# STM32MP25_CM33 register map
File version: 1.3
CPU: CM33 r0p1, little endian, MPU, FPU, vendor SysTick, 8 interrupt priority bits
Registers are 32-bit, read-write, reset 0x0 unless marked. A register's access mark holds for its fields unless they carry their own. Offsets are from the block's base; [hi:lo] are bit positions; {n}, {i} and the like mark numbered series; 'fields as' and 'values as' point back to an identical list.

## RIFSC — RIFSC register block
Base 0x42080000
Same registers: RIFSC_S 0x52080000
0x00 RIFSC_RISC_CR — RIFSC RISC slave configuration register x
  [0] GLOCK — Global lock This bit locks the configuration of RIFSC RISC registers until next reset. This bit is cleared by default and, once set, it cannot be reset until global RIFSC reset.
    0=RIFSC RISC registers are writable; 1=All writes to RIFSC RISC registers are ignored, except RIFSC_RISC_PERy_SEMCR
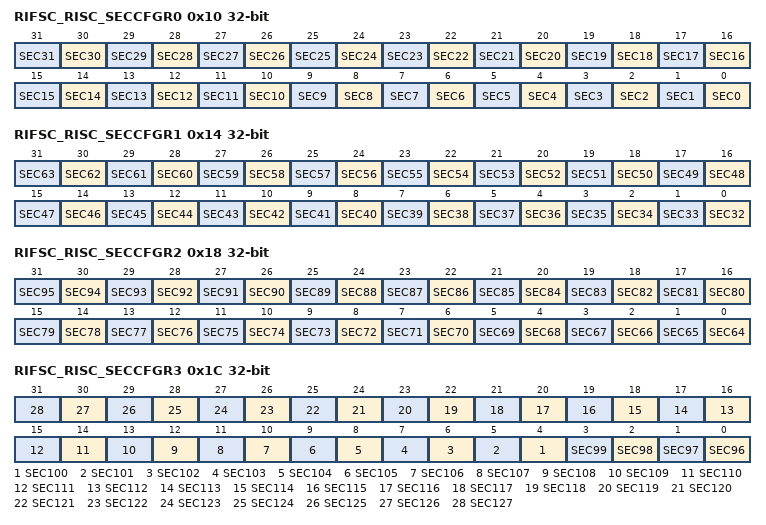
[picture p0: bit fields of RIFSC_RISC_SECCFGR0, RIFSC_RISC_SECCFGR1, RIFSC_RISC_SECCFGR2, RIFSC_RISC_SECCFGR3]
0x10 RIFSC_RISC_SECCFGR0 — RIFSC RISC slave security configuration register 0
  [n] SEC{n} (n=0..31) — Security configuration for peripheral {n} Note: Regardless of SEC value, any execute access to peripheral {n} triggers a bus error. Note: If the compartment filtering for peripheral {n} is enabled (resp. disabled) using CFEN in RIFSC_RISC_PERy_CIDCFGR, only an authorized compartment (resp. any compartment) can write this bit, if privilege and security of the access is sufficient. Note: Authorized compartment is defined as SCID if SEM_EN=0 in RIFSC_RISC_PERy_CIDCFGR. If SEM_EN=1, it is equal to SEMCID, if SEM_MUTEX=1 in RIFSC_RISC_PERy_SEMCR. There is no authorized compartment if SEM_EN=1 and SEM_MUTEX=0.
    0=Secure and non-secure data access are granted to the peripheral {n}; 1=Secure data access only are granted to the peripheral {n}
0x14 RIFSC_RISC_SECCFGR1 — RIFSC RISC slave security configuration register 1
  [n-32] SEC{n} (n=32..63) — Security configuration for peripheral {n} Note: Regardless of SEC value, any execute access to peripheral {n} triggers a bus error. Note: If the compartment filtering for peripheral {n} is enabled (resp. disabled) using CFEN in RIFSC_RISC_PERy_CIDCFGR, only an authorized compartment (resp. any compartment) can write this bit, if privilege and security of the access is sufficient. Note: Authorized compartment is defined as SCID if SEM_EN=0 in RIFSC_RISC_PERy_CIDCFGR. If SEM_EN=1, it is equal to SEMCID, if SEM_MUTEX=1 in RIFSC_RISC_PERy_SEMCR. There is no authorized compartment if SEM_EN=1 and SEM_MUTEX=0.
    values as RIFSC_RISC_SECCFGR0.SEC0
0x18 RIFSC_RISC_SECCFGR2 — RIFSC RISC slave security configuration register 2
  [n-64] SEC{n} (n=64..95) — Security configuration for peripheral {n} Note: Regardless of SEC value, any execute access to peripheral {n} triggers a bus error. Note: If the compartment filtering for peripheral {n} is enabled (resp. disabled) using CFEN in RIFSC_RISC_PERy_CIDCFGR, only an authorized compartment (resp. any compartment) can write this bit, if privilege and security of the access is sufficient. Note: Authorized compartment is defined as SCID if SEM_EN=0 in RIFSC_RISC_PERy_CIDCFGR. If SEM_EN=1, it is equal to SEMCID, if SEM_MUTEX=1 in RIFSC_RISC_PERy_SEMCR. There is no authorized compartment if SEM_EN=1 and SEM_MUTEX=0.
    values as RIFSC_RISC_SECCFGR0.SEC0
0x1C RIFSC_RISC_SECCFGR3 — RIFSC RISC slave security configuration register 3
  [n-96] SEC{n} (n=96..127) — Security configuration for peripheral {n} Note: Regardless of SEC value, any execute access to peripheral {n} triggers a bus error. Note: If the compartment filtering for peripheral {n} is enabled (resp. disabled) using CFEN in RIFSC_RISC_PERy_CIDCFGR, only an authorized compartment (resp. any compartment) can write this bit, if privilege and security of the access is sufficient. Note: Authorized compartment is defined as SCID if SEM_EN=0 in RIFSC_RISC_PERy_CIDCFGR. If SEM_EN=1, it is equal to SEMCID, if SEM_MUTEX=1 in RIFSC_RISC_PERy_SEMCR. There is no authorized compartment if SEM_EN=1 and SEM_MUTEX=0.
    values as RIFSC_RISC_SECCFGR0.SEC0
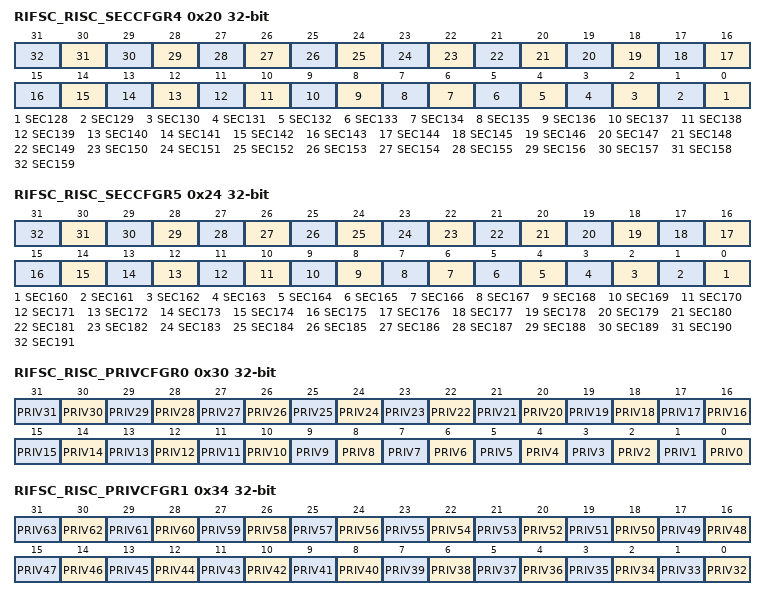
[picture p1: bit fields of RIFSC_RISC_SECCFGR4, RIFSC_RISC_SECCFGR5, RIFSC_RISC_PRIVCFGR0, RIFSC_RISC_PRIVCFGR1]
0x20 RIFSC_RISC_SECCFGR4 — RIFSC RISC slave security configuration register 4
  [n-128] SEC{n} (n=128..159) — Security configuration for peripheral {n} Note: Regardless of SEC value, any execute access to peripheral {n} triggers a bus error. Note: If the compartment filtering for peripheral {n} is enabled (resp. disabled) using CFEN in RIFSC_RISC_PERy_CIDCFGR, only an authorized compartment (resp. any compartment) can write this bit, if privilege and security of the access is sufficient. Note: Authorized compartment is defined as SCID if SEM_EN=0 in RIFSC_RISC_PERy_CIDCFGR. If SEM_EN=1, it is equal to SEMCID, if SEM_MUTEX=1 in RIFSC_RISC_PERy_SEMCR. There is no authorized compartment if SEM_EN=1 and SEM_MUTEX=0.
    values as RIFSC_RISC_SECCFGR0.SEC0
0x24 RIFSC_RISC_SECCFGR5 — RIFSC RISC slave security configuration register 5
  [n-160] SEC{n} (n=160..191) — Security configuration for peripheral {n} Note: Regardless of SEC value, any execute access to peripheral {n} triggers a bus error. Note: If the compartment filtering for peripheral {n} is enabled (resp. disabled) using CFEN in RIFSC_RISC_PERy_CIDCFGR, only an authorized compartment (resp. any compartment) can write this bit, if privilege and security of the access is sufficient. Note: Authorized compartment is defined as SCID if SEM_EN=0 in RIFSC_RISC_PERy_CIDCFGR. If SEM_EN=1, it is equal to SEMCID, if SEM_MUTEX=1 in RIFSC_RISC_PERy_SEMCR. There is no authorized compartment if SEM_EN=1 and SEM_MUTEX=0.
    values as RIFSC_RISC_SECCFGR0.SEC0
0x30 RIFSC_RISC_PRIVCFGR0 — RIFSC RISFC slave privileged register 0
  [n] PRIV{n} (n=0..31) — Privileged-only access permission for peripheral {n} Note: If corresponding SEC{n} bit is set in RIFSC_RISC_SECCFGRx, this bit can only be written by a secure privileged application. Note: If the compartment filtering for peripheral {n} is enabled (resp. disabled) using CFEN in RIFSC_RISC_PERy_CIDCFGR, only an authorized compartment (resp. any compartment) can write this bit, if privilege and security of the access is sufficient. Note: Authorized compartment is defined as SCID if SEM_EN=0 in RIFSC_RISC_PERy_CIDCFGR. If SEM_EN=1, it is equal to SEMCID, if SEM_MUTEX=1 in RIFSC_RISC_PERy_SEMCR. There is no authorized compartment if SEM_EN=1 and SEM_MUTEX=0.
    0=Privileged and unprivileged data access are granted to the peripheral {n}; 1=Privileged data access only are granted to the peripheral {n}
0x34 RIFSC_RISC_PRIVCFGR1 — RIFSC RISFC slave privileged register 1
  [n-32] PRIV{n} (n=32..63) — Privileged-only access permission for peripheral {n} Note: If corresponding SEC{n} bit is set in RIFSC_RISC_SECCFGRx, this bit can only be written by a secure privileged application. Note: If the compartment filtering for peripheral {n} is enabled (resp. disabled) using CFEN in RIFSC_RISC_PERy_CIDCFGR, only an authorized compartment (resp. any compartment) can write this bit, if privilege and security of the access is sufficient. Note: Authorized compartment is defined as SCID if SEM_EN=0 in RIFSC_RISC_PERy_CIDCFGR. If SEM_EN=1, it is equal to SEMCID, if SEM_MUTEX=1 in RIFSC_RISC_PERy_SEMCR. There is no authorized compartment if SEM_EN=1 and SEM_MUTEX=0.
    values as RIFSC_RISC_PRIVCFGR0.PRIV0
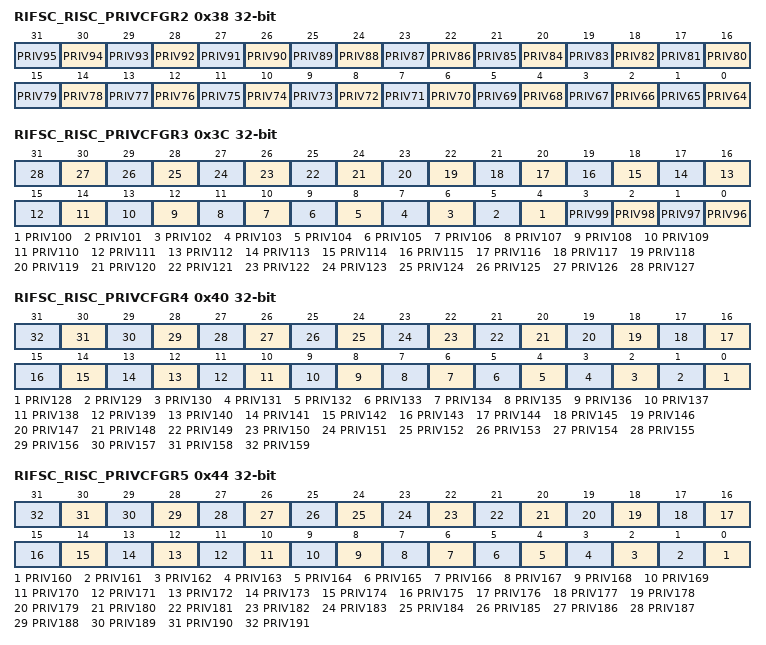
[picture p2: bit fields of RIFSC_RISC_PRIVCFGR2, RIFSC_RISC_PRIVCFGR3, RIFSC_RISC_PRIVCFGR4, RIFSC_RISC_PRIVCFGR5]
0x38 RIFSC_RISC_PRIVCFGR2 — RIFSC RISFC slave privileged register 2
  [n-64] PRIV{n} (n=64..95) — Privileged-only access permission for peripheral {n} Note: If corresponding SEC{n} bit is set in RIFSC_RISC_SECCFGRx, this bit can only be written by a secure privileged application. Note: If the compartment filtering for peripheral {n} is enabled (resp. disabled) using CFEN in RIFSC_RISC_PERy_CIDCFGR, only an authorized compartment (resp. any compartment) can write this bit, if privilege and security of the access is sufficient. Note: Authorized compartment is defined as SCID if SEM_EN=0 in RIFSC_RISC_PERy_CIDCFGR. If SEM_EN=1, it is equal to SEMCID, if SEM_MUTEX=1 in RIFSC_RISC_PERy_SEMCR. There is no authorized compartment if SEM_EN=1 and SEM_MUTEX=0.
    values as RIFSC_RISC_PRIVCFGR0.PRIV0
0x3C RIFSC_RISC_PRIVCFGR3 — RIFSC RISFC slave privileged register 3
  [n-96] PRIV{n} (n=96..127) — Privileged-only access permission for peripheral {n} Note: If corresponding SEC{n} bit is set in RIFSC_RISC_SECCFGRx, this bit can only be written by a secure privileged application. Note: If the compartment filtering for peripheral {n} is enabled (resp. disabled) using CFEN in RIFSC_RISC_PERy_CIDCFGR, only an authorized compartment (resp. any compartment) can write this bit, if privilege and security of the access is sufficient. Note: Authorized compartment is defined as SCID if SEM_EN=0 in RIFSC_RISC_PERy_CIDCFGR. If SEM_EN=1, it is equal to SEMCID, if SEM_MUTEX=1 in RIFSC_RISC_PERy_SEMCR. There is no authorized compartment if SEM_EN=1 and SEM_MUTEX=0.
    values as RIFSC_RISC_PRIVCFGR0.PRIV0
0x40 RIFSC_RISC_PRIVCFGR4 — RIFSC RISFC slave privileged register 4
  [n-128] PRIV{n} (n=128..159) — Privileged-only access permission for peripheral {n} Note: If corresponding SEC{n} bit is set in RIFSC_RISC_SECCFGRx, this bit can only be written by a secure privileged application. Note: If the compartment filtering for peripheral {n} is enabled (resp. disabled) using CFEN in RIFSC_RISC_PERy_CIDCFGR, only an authorized compartment (resp. any compartment) can write this bit, if privilege and security of the access is sufficient. Note: Authorized compartment is defined as SCID if SEM_EN=0 in RIFSC_RISC_PERy_CIDCFGR. If SEM_EN=1, it is equal to SEMCID, if SEM_MUTEX=1 in RIFSC_RISC_PERy_SEMCR. There is no authorized compartment if SEM_EN=1 and SEM_MUTEX=0.
    values as RIFSC_RISC_PRIVCFGR0.PRIV0
0x44 RIFSC_RISC_PRIVCFGR5 — RIFSC RISFC slave privileged register 5
  [n-160] PRIV{n} (n=160..191) — Privileged-only access permission for peripheral {n} Note: If corresponding SEC{n} bit is set in RIFSC_RISC_SECCFGRx, this bit can only be written by a secure privileged application. Note: If the compartment filtering for peripheral {n} is enabled (resp. disabled) using CFEN in RIFSC_RISC_PERy_CIDCFGR, only an authorized compartment (resp. any compartment) can write this bit, if privilege and security of the access is sufficient. Note: Authorized compartment is defined as SCID if SEM_EN=0 in RIFSC_RISC_PERy_CIDCFGR. If SEM_EN=1, it is equal to SEMCID, if SEM_MUTEX=1 in RIFSC_RISC_PERy_SEMCR. There is no authorized compartment if SEM_EN=1 and SEM_MUTEX=0.
    values as RIFSC_RISC_PRIVCFGR0.PRIV0
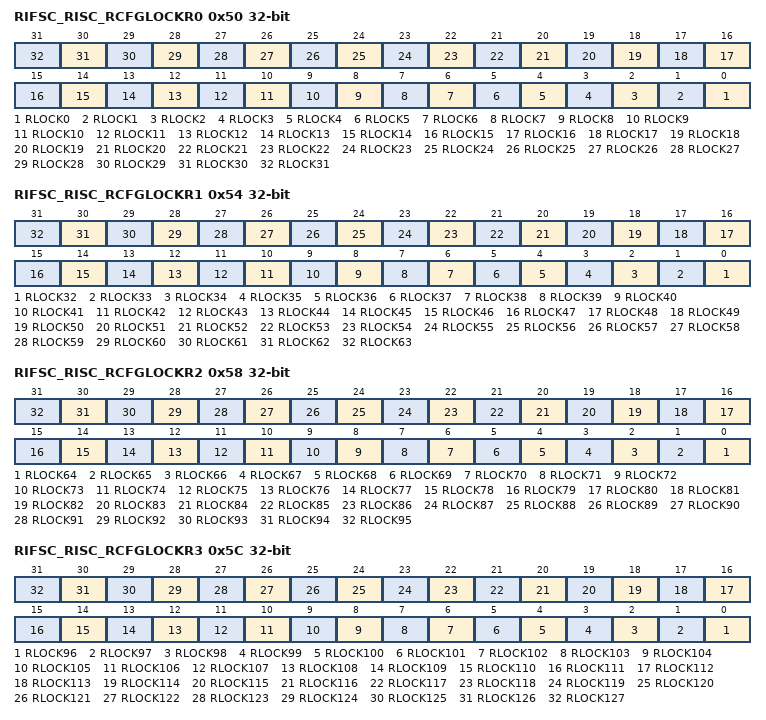
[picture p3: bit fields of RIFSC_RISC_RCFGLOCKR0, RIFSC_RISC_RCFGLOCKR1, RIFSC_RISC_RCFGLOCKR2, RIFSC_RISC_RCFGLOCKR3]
0x50 RIFSC_RISC_RCFGLOCKR0 — RIFSC RISC slave resource configuration lock register 0
  [n] RLOCK{n} (n=0..31) — rRsource lock for peripheral {n} This bit is set to lock the peripheral resource {n}. It is cleared by default and, once set, this bit cannot be cleared until the RIFSC RISC peripheral is reset. in RIFSC_RISC_PRIVCFGRx are writable. RIFSC_RISC_PERy_CIDCFGR is writable. to RIFSC_RISC_PERy_CIDCFGR register are ignored.
    0=SEC{n} in RIFSC_RISC_SECCFGRx and PRIV{n}; 1=Writes to SEC{n} and PRIV{n} are ignored. Writes
0x54 RIFSC_RISC_RCFGLOCKR1 — RIFSC RISC slave resource configuration lock register 1
  [n-32] RLOCK{n} (n=32..63) — rRsource lock for peripheral {n} This bit is set to lock the peripheral resource {n}. It is cleared by default and, once set, this bit cannot be cleared until the RIFSC RISC peripheral is reset. in RIFSC_RISC_PRIVCFGRx are writable. RIFSC_RISC_PERy_CIDCFGR is writable. to RIFSC_RISC_PERy_CIDCFGR register are ignored.
    values as RIFSC_RISC_RCFGLOCKR0.RLOCK0
0x58 RIFSC_RISC_RCFGLOCKR2 — RIFSC RISC slave resource configuration lock register 2
  [n-64] RLOCK{n} (n=64..95) — rRsource lock for peripheral {n} This bit is set to lock the peripheral resource {n}. It is cleared by default and, once set, this bit cannot be cleared until the RIFSC RISC peripheral is reset. in RIFSC_RISC_PRIVCFGRx are writable. RIFSC_RISC_PERy_CIDCFGR is writable. to RIFSC_RISC_PERy_CIDCFGR register are ignored.
    values as RIFSC_RISC_RCFGLOCKR0.RLOCK0
0x5C RIFSC_RISC_RCFGLOCKR3 — RIFSC RISC slave resource configuration lock register 3
  [n-96] RLOCK{n} (n=96..127) — rRsource lock for peripheral {n} This bit is set to lock the peripheral resource {n}. It is cleared by default and, once set, this bit cannot be cleared until the RIFSC RISC peripheral is reset. in RIFSC_RISC_PRIVCFGRx are writable. RIFSC_RISC_PERy_CIDCFGR is writable. to RIFSC_RISC_PERy_CIDCFGR register are ignored.
    values as RIFSC_RISC_RCFGLOCKR0.RLOCK0
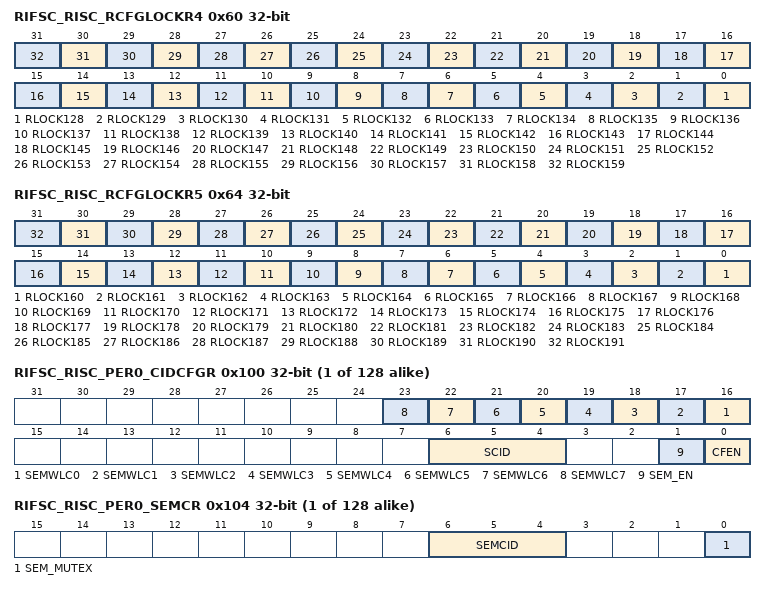
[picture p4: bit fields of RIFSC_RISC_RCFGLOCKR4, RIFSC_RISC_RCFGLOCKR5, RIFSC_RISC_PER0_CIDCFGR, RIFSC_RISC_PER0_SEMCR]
0x60 RIFSC_RISC_RCFGLOCKR4 — RIFSC RISC slave resource configuration lock register 4
  [n-128] RLOCK{n} (n=128..159) — rRsource lock for peripheral {n} This bit is set to lock the peripheral resource {n}. It is cleared by default and, once set, this bit cannot be cleared until the RIFSC RISC peripheral is reset. in RIFSC_RISC_PRIVCFGRx are writable. RIFSC_RISC_PERy_CIDCFGR is writable. to RIFSC_RISC_PERy_CIDCFGR register are ignored.
    values as RIFSC_RISC_RCFGLOCKR0.RLOCK0
0x64 RIFSC_RISC_RCFGLOCKR5 — RIFSC RISC slave resource configuration lock register 5
  [n-160] RLOCK{n} (n=160..191) — rRsource lock for peripheral {n} This bit is set to lock the peripheral resource {n}. It is cleared by default and, once set, this bit cannot be cleared until the RIFSC RISC peripheral is reset. in RIFSC_RISC_PRIVCFGRx are writable. RIFSC_RISC_PERy_CIDCFGR is writable. to RIFSC_RISC_PERy_CIDCFGR register are ignored.
    values as RIFSC_RISC_RCFGLOCKR0.RLOCK0
{0x100+8i} RIFSC_RISC_PER{i}_CIDCFGR (i=0..127) — RIFSC RISC slave peripheral {i} CID configuration register
  [n+16] SEMWLC{n} (n=0..7) — Semaphore white list for compartment i Note: This bit is not taken into account by RISC when the semaphore is disabled (SEM_EN=0) or compartment filtering is off (CFEN=0).
    0=Application running in compartment i cannot get access to peripheral y through the semaphore SEM_MUTEX; 1=Application running in compartment i can get access to peripheral y through the semaphore SEM_MUTEX
  [6:4] SCID — Static CID The trusted domain application uses this bit field to statically define which compartment has access to the peripheral y when SEM_EN = 0. This CID is not taken into account by RISC when the semaphore is enabled Note: (SEM_EN = 1) or compartment filtering is off (CFEN = 0).
  [1] SEM_EN — Semaphore enable to SEMCID in RIFSC_RISC_PERy_SEMCR. Note: This bit is not taken into account by RISC if the compartment filtering is off (CFEN = 0). When this bit is cleared from 1 by the trusted domain application, SEM_MUTEX is cleared to zero by RISC.
    0=Access to peripheral y is granted only if CID of the access equals to SCID; 1=Access to peripheral y is granted only if SEM_MUTEX = 1 and CID of the access equals
  [0] CFEN — CID filtering enable For any CFEN value, access controls to peripheral y defined in RIFSC_RISC_PRIVCFGRx and RIFSC_RISC_SECCFGRx always apply. Note: When this bit is cleared from 1 by the trusted domain application, SEM_MUTEX is cleared to zero by RISC.
    0=Compartment-based filtering defined in RIFSC_RISC_PERy_CIDCFGR and optionally RIFSC_RISC_PERy_SEMCR is disabled for peripheral y; 1=Compartment-based filtering defined in RIFSC_RISC_PERy_CIDCFGR and optionally RIFSC_RISC_PERy_SEMCR is enabled for peripheral y
{0x104+8i} RIFSC_RISC_PER{i}_SEMCR (i=0..127) — RIFSC RISC slave peripheral {i} semaphore control register
  [6:4] SEMCID ro — Semaphore current CID When SEM_EN and CFEN are set in RIFSC_RISC_PERy_CIDCFGR, this read-only bit field is updated with the CID value of the latest successful acquisition of RIFSC_RISC_PERy_SEMCR semaphore (SEM_MUTEX = 1). In all the other cases, this bit field stays unchanged.
  [0] SEM_MUTEX — Semaphore mutex A white-listed application can set this bit to get exclusive access to peripheral y when SEM_EN is set in RIFSC_RISC_PERy_CIDCFGR (writes are ignored otherwise). Read 0: Semaphore is free to take. Read 1: Semaphore is taken. Write 0: Release semaphore. Write 1: Acquire semaphore. Note: When SEM_MUTEX = 0, only applications belonging to white-listed compartments (defined with SEMWLCi bits in RIFSC_RISC_PERy_CIDCFGR) can acquire this semaphore. Note: When SEM_MUTEX = 1, only applications belonging to compartment SEMCID can release this semaphore. Note: This bit is cleared when CFEN or SEM_EN are cleared from 1 by the trusted domain application in RIFSC_RISC_PERy_CIDCFGR.
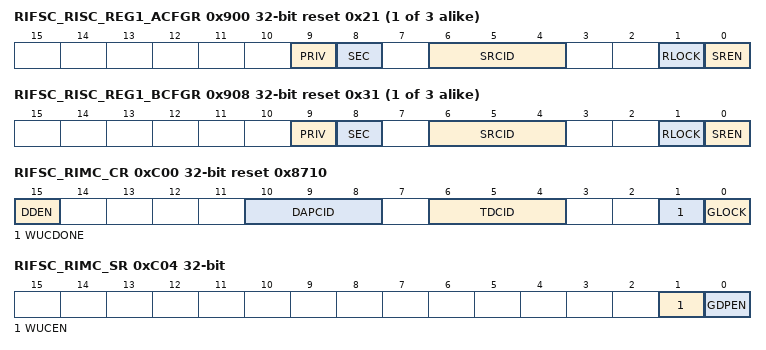
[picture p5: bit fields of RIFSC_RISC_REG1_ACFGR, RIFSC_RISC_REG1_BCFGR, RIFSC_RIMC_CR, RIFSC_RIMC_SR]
{0x8F0+0x10*i} RIFSC_RISC_REG{i}_ACFGR reset 0x21 (i=1..3) — RIFSC RISAL memory region {i} subregion z configuration register
  [9] PRIV — Privileged subregion This bit is taken into account only if SREN = 1. Note: Access control defined by SEC and SRCID[2:0] also apply.
    0=Privileged and unprivileged accesses are granted in subregion z of region x; 1=Only privileged accesses are granted in subregion z of region x
  [8] SEC — Secure subregion This bit is taken into account only if SREN = 1. Note: Access control defined by PRIV and SRCID[2:0] also apply.
    0=Only non-secure requests can access subregion z of region x; 1=Only secure requests can access subregion z of region x
  [6:4] SRCID — Subregion CID When SREN = 1, this bit field defines which compartment has access to the subregion z of region x.
  [1] RLOCK — Resource lock This bit is set to lock this subregion resource. This bit is set once, cleared only by RIFSC reset.
    0=RIFSC_RISC_REGx_zCFGR and RIFSC_RISC_REGx_zADDR are writable; 1=Writes to RIFSC_RISC_REGx_zCFGR and RIFSC_RISC_REGx_zADDR are ignored
  [0] SREN — Subregion enable
    0=Subregion z is disabled. Only secure, privileged, and trusted domain CID can access between this subregion start and end addresses.; 1=Subregion z of region x is enabled. Access control defined in this subregion applies to any access between this subregion start and end addresses.
{0x8F8+0x10*i} RIFSC_RISC_REG{i}_BCFGR reset 0x31 (i=1..3) — RIFSC RISAL memory region {i} subregion z configuration register
  fields as RIFSC_RISC_REG1_ACFGR
0xC00 RIFSC_RIMC_CR rw-once reset 0x8710 — RIFSC RIMC master configuration register
  [15] DDEN ro — Debug domain enable This read-only bit gives the status on the debug domain feature availability on this device.
    0=Debug domain not available; 1=Debug domain available
  [10:8] DAPCID rw — Debug access port compartment ID This bit field defines the CID of the DAP when GDPEN is set in RIFSC_RIMC_SR. When DAPCID[2:0] = 0x7, debugging tools have the highest level of debug access, if secure global debug profile is enabled in the BSEC peripheral. When GDPEN = 0, DAPCID[2:0] can be written by trusted application (TDCID secure privileged). When GDPEN = 1, the DAP can also change this bit field regardless of the access type (secure, non-secure, privileged, or unprivileged).
  [6:4] TDCID — Trusted domain compartment ID Master with this compartment ID runs the application with the highest level of trust. TDCID[2:0] value is distributed in all the device. This bit field is write once (subsequent writes are ignored). Note: Secure privileged write access only. Write only by debug domain and trusted domain CIDs, as defined in this register.
  [1] WUCDONE rw — Wake-up CPU done Setting this bit deactivates the wake-up CPU mechanism described in Section5.2: Resource isolation framework (RIF). Reading this bit always returns zero. Note: Secure privileged write access only. Write only by debug domain and trusted domain CIDs, as defined in this register (including this bit).
    0=When WUCEN = 1 in RIFSC_RIMC_SR, the trusted domain CID information is fixed to0x2 (wake-up CPU), else it is defined in this register; 1=Setting this bit clears WUCEN after few cycles. Once WUCEN =0, the trusted domain CID information is defined in this register.
  [0] GLOCK rw — Global lock This bit is used to lock the configuration of RIFSC RIMC registers until next reset. This bit is cleared by default and, once set, it cannot be reset until global RIFSC reset. Note: Secure privileged write access only. Write only by debug domain and trusted domain CIDs, as defined in this register.
    0=RIFSC RIMC registers are writable; 1=All writes to RIFSC RIMC registers are ignored
0xC04 RIFSC_RIMC_SR ro — RIFSC RIMC master status register
  [1] WUCEN — Wake-up CPU enable This read-only bit is set when the application properly initializes the wake-up CPU mechanism described in Section5.2: Resource isolation framework (RIF).
    0=Wake-up CPU is disabled. The trusted domain CID value is driven by RIFSC_RIMC_CR.; 1=Wake-up CPU is enabled. The trusted domain CID value is fixed to 0x2 until the application sets WUCDONE in RIFSC_RIMC_CR (in this case, WUCDONE is cleared after few cycles).
  [0] GDPEN — Global debug profile enable This read-only bit is set when the global-debug profile is activated in the device (CPU and MCU debugging allowed).
    0=Global-debug profile (CPU + MCU) is not activated; 1=Global-debug profile (CPU + MCU) is activated
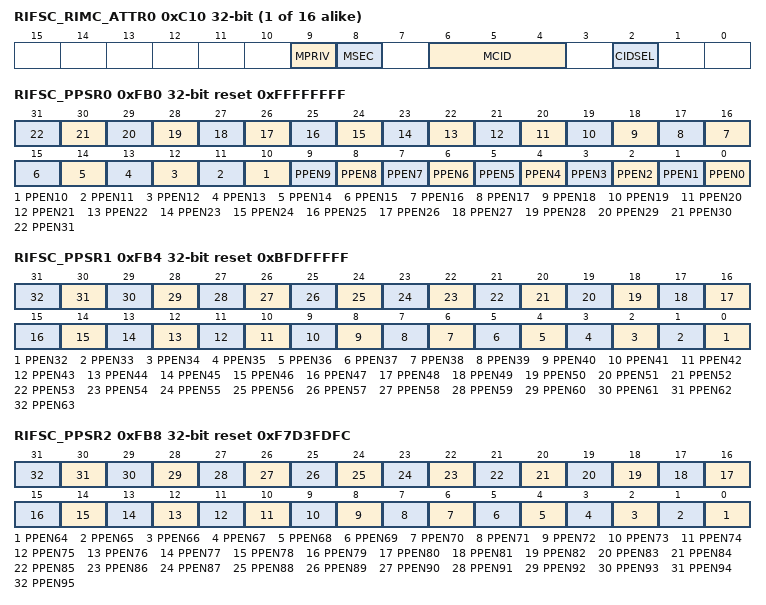
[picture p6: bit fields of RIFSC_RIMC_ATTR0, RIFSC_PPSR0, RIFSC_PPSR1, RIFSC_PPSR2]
{0xC10+4i} RIFSC_RIMC_ATTR{i} (i=0..15) — RIFSC RIMC master attribute register {i}
  [9] MPRIV — Master privileged Value of the privileged flag on the interconnect for this master, programmed by the trusted domain.
    0=This master is unprivileged; 1=This master is privileged
  [8] MSEC — Master secure Value of the secure flag on the interconnect for this master, programmed by the trusted domain.
    0=This master is non-secure; 1=This master is secure
  [6:4] MCID — Master CID Value of the CID flag on the interconnect for this master, programmed by the trusted domain. Valid only if indicated in RIF masters table in Section8.3. This bit field is not taken into account when CIDSEL = 0 in this register. This bit field cannot be written with a value of 0x7 (write to MCID[2:0] is ignored).
  [2] CIDSEL — CID selection
    0=Compartment ID of master x is driven by hardware value or by inheritance to associated RISUP. See master table in Section8.3 for details.; 1=Compartment ID of master x is defined by MCID[2:0] in this register
0xFB0 RIFSC_PPSR0 ro reset 0xFFFFFFFF — RIFSC peripheral protection status register 0
  [n] PPEN{n} (n=0..31) — Peripheral protection enable {n}
    0=RISUP protection to peripheral {n} is not present. The corresponding RIFSC_RISC_PERy_CIDCFGR and RIFSC_RISC_PERy_SEMCR (where y = i + 32 * x) are reserved.; 1=RISUP protection to peripheral {n} is present
0xFB4 RIFSC_PPSR1 ro reset 0xBFDFFFFF — RIFSC peripheral protection status register 1
  [n-32] PPEN{n} (n=32..63) — Peripheral protection enable {n}
    values as RIFSC_PPSR0.PPEN0
0xFB8 RIFSC_PPSR2 ro reset 0xF7D3FDFC — RIFSC peripheral protection status register 2
  [n-64] PPEN{n} (n=64..95) — Peripheral protection enable {n}
    values as RIFSC_PPSR0.PPEN0
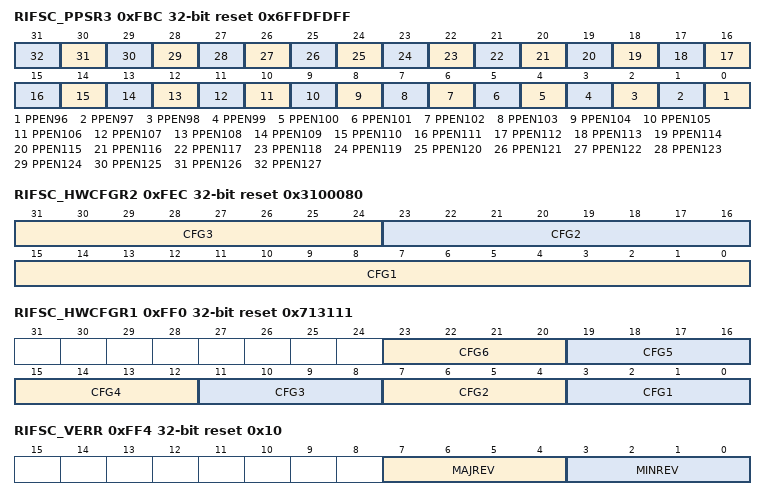
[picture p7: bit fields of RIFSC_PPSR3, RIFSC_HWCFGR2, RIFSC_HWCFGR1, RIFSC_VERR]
0xFBC RIFSC_PPSR3 ro reset 0x6FFDFDFF — RIFSC peripheral protection status register 3
  [n-96] PPEN{n} (n=96..127) — Peripheral protection enable {n}
    values as RIFSC_PPSR0.PPEN0
0xFE8 RIFSC_HWCFGR3 ro reset 0x3 — RIFSC hardware configuration register 3
  [31:0] CFG — Hardware configuration This bit field returns the generic value RISAL_FIXED_LENGTH.
0xFEC RIFSC_HWCFGR2 ro reset 0x3100080 — RIFSC hardware configuration register 2
  [31:24] CFG3 — Hardware configuration 3 This bit field returns the generic value NUM_RISAL (0x3).
  [23:16] CFG2 — Hardware configuration 2 This bit field returns the generic value NUM_MP (0x10).
  [15:0] CFG1 — Hardware configuration 1 This bit field returns the generic value NUM_SP (0x80).
0xFF0 RIFSC_HWCFGR1 ro reset 0x713111 — RIFSC hardware configuration register 1
  [23:20] CFG6 — Hardware configuration 6 This bit field returns the generic value DEFAULT_DAPCID.
  [19:16] CFG5 — Hardware configuration 5 This bit field returns the generic value DEFAULT_TDCID.
  [15:12] CFG4 — Hardware configuration 4 This bit field returns the generic value CID_WIDTH.
  [11:8] CFG3 — Hardware configuration 3 This bit field returns the generic value PRIV_ENABLED.
  [7:4] CFG2 — Hardware configuration 2 This bit field returns the generic value SEC_ENABLED.
  [3:0] CFG1 — Hardware configuration 1 This bit field returns the generic value RIF_ENABLED.
0xFF4 RIFSC_VERR ro reset 0x10 — RIFSC version register
  [7:4] MAJREV — RIFSC major revision
  [3:0] MINREV — RIFSC minor revision
0xFF8 RIFSC_IPIDR ro reset 0x100162 — RIFSC identification register
  [31:0] ID — RIFSC identification code
0xFFC RIFSC_SIDR ro reset 0xA3C5DD04 — RIFSC size identification register
  [31:0] SID — RIFSC size identification code Bits[31:8] = 0xA3C5DD (fixed code) Bits[7:0] = 0x04 (4-Kbyte address decoding)
